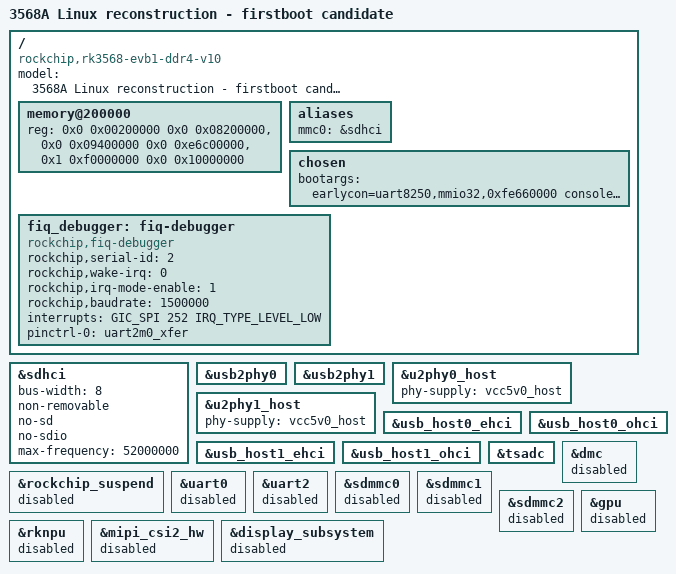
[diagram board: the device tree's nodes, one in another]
// SPDX-License-Identifier: (GPL-2.0+ OR MIT)
/* Offline reconstruction candidate. See ../RECONSTRUCTION.md before booting. */
/dts-v1/;

/* Captured boot-time reservations, NOT an independently verified loader ABI. */
/memreserve/ 0x0a100000 0x25000;
/memreserve/ 0x0a200000 0xc8c20;

#include "rk3568.dtsi"
#include "rk3568-aiot-3568pq-power.dtsi"

/ {
    model = "3568A Linux reconstruction - firstboot candidate";
    compatible = "rockchip,rk3568-evb1-ddr4-v10", "rockchip,rk3568";

    /* Preserve the observed holes and high remap, not a guessed contiguous 4GB.
     * Bootloader memory fixups and Image/initramfs addresses still need review.
     * Zero-length padding entries from the running FDT have been omitted.
     */
    memory@200000 {
        device_type = "memory";
        reg = <0x0 0x00200000 0x0 0x08200000>,
              <0x0 0x09400000 0x0 0xe6c00000>,
              <0x1 0xf0000000 0x0 0x10000000>;
    };

    aliases {
        mmc0 = &sdhci;
    };

    chosen {
        /* Supplied initramfs /init must mount proc/sys/dev explicitly.
         * No Android partition is selected as root. No initramfs is built here.
         */
        bootargs = "earlycon=uart8250,mmio32,0xfe660000 console=ttyFIQ0 rdinit=/init ro";
    };

    fiq_debugger: fiq-debugger {
        compatible = "rockchip,fiq-debugger";
        rockchip,serial-id = <2>;
        rockchip,wake-irq = <0>;
        rockchip,irq-mode-enable = <1>;
        rockchip,baudrate = <1500000>;
        interrupts = <GIC_SPI 252 IRQ_TYPE_LEVEL_LOW>;
        pinctrl-names = "default";
        pinctrl-0 = <&uart2m0_xfer>;
        status = "okay";
    };
};

&sdhci {
    bus-width = <8>;
    non-removable;
    no-sd;
    no-sdio;
    /* Target dwcmshc driver clears HS200/HS400/DDR capabilities at <=52MHz. */
    max-frequency = <52000000>;
    status = "okay";
};

/* Both Android USB2 host controllers were enumerated. No inferred power GPIO. */
&usb2phy0 { status = "okay"; };
&usb2phy1 { status = "okay"; };
&u2phy0_host {
    phy-supply = <&vcc5v0_host>;
    status = "okay";
};
&u2phy1_host {
    phy-supply = <&vcc5v0_host>;
    status = "okay";
};
&usb_host0_ehci { status = "okay"; };
&usb_host0_ohci { status = "okay"; };
&usb_host1_ehci { status = "okay"; };
&usb_host1_ohci { status = "okay"; };

&tsadc { status = "okay"; };

/* Do not activate unreviewed voltage/frequency, actuator, or peripheral paths. */
&dmc { status = "disabled"; };
&rockchip_suspend { status = "disabled"; };
&uart0 { status = "disabled"; };
&uart2 { status = "disabled"; }; /* Owned by fiq-debugger, not 8250. */
&sdmmc0 { status = "disabled"; };
&sdmmc1 { status = "disabled"; };
&sdmmc2 { status = "disabled"; };
&gpu { status = "disabled"; };
&rknpu { status = "disabled"; };
&mipi_csi2_hw { status = "disabled"; };
&display_subsystem { status = "disabled"; };
